# STM32G474xx register map
File version: 1.6
CPU: CM4 r0p1, little endian, MPU, FPU, 4 interrupt priority bits
Registers are 32-bit, read-write, reset 0x0 unless marked. A register's access mark holds for its fields unless they carry their own. Offsets are from the block's base; [hi:lo] are bit positions; {n}, {i} and the like mark numbered series; 'fields as' and 'values as' point back to an identical list.

## EXTI — External interrupt/event controller
Base 0x40010400
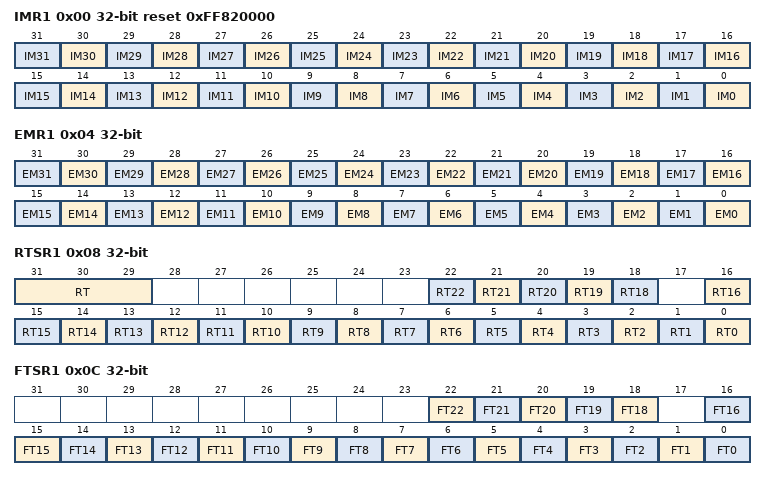
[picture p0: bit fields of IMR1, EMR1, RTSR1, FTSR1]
0x00 IMR1 reset 0xFF820000 — Interrupt mask register
  [n] IM{n} (n=0..31) — Interrupt Mask on line {n}
0x04 EMR1 — Event mask register
  [n] EM{n} (n=0..31) — Event Mask on line {n}
0x08 RTSR1 — Rising Trigger selection register
  [31:29] RT
  [n] RT{n} (n=18..22) — Rising trigger event configuration of line {n}
  [n] RT{n} (n=0..16) — Rising trigger event configuration of line {n}
0x0C FTSR1 — Falling Trigger selection register
  [n] FT{n} (n=18..22) — Falling trigger event configuration of line {n}
  [n] FT{n} (n=0..16) — Falling trigger event configuration of line {n}
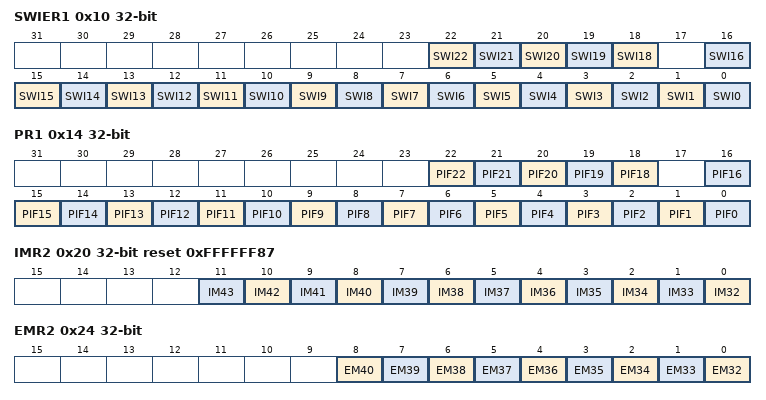
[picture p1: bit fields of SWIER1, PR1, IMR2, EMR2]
0x10 SWIER1 — Software interrupt event register
  [n] SWI{n} (n=18..22) — Software Interrupt on line {n}
  [n] SWI{n} (n=0..16) — Software Interrupt on line {n}
0x14 PR1 — Pending register
  [n] PIF{n} (n=18..22) — Pending bit {n}
  [n] PIF{n} (n=0..16) — Pending bit {n}
0x20 IMR2 reset 0xFFFFFF87 — Interrupt mask register
  [n-32] IM{n} (n=32..43) — Interrupt Mask on external/internal line {n}
0x24 EMR2 — Event mask register
  [n-32] EM{n} (n=32..40) — Event mask on external/internal line {n}
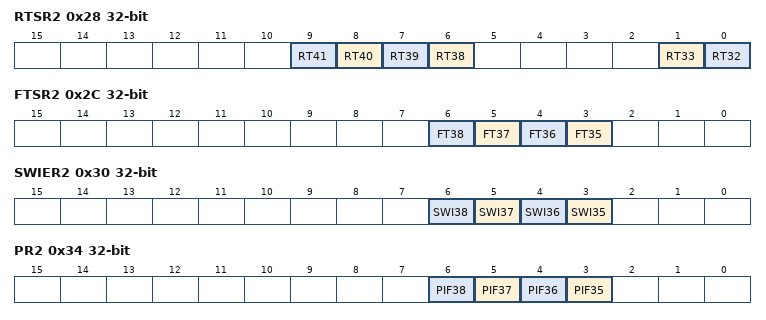
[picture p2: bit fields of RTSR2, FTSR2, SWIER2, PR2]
0x28 RTSR2 — Rising Trigger selection register
  [n-32] RT{n} (n=38..41) — Rising trigger event configuration bit of line {n}
  [1] RT33 — Rising trigger event configuration bit of line 32
  [0] RT32 — Rising trigger event configuration bit of line 32
0x2C FTSR2 — Falling Trigger selection register
  [n-32] FT{n} (n=35..38) — Falling trigger event configuration bit of line {n}
0x30 SWIER2 — Software interrupt event register
  [n-32] SWI{n} (n=35..38) — Software interrupt on line {n}
0x34 PR2 — Pending register
  [n-32] PIF{n} (n=35..38) — Pending interrupt flag on line {n}

## FMC — Flexible memory controller
Base 0xA0000000
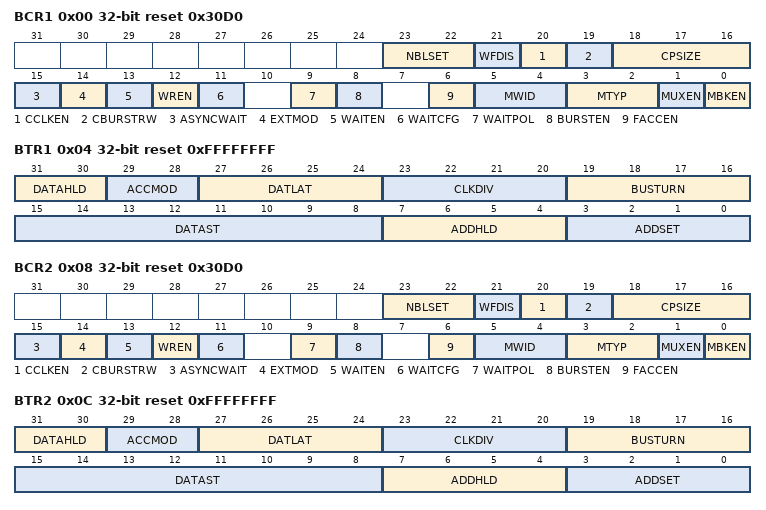
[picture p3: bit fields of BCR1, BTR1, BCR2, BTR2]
0x00 BCR1 reset 0x30D0 — SRAM/NOR-Flash chip-select control register 1
  [23:22] NBLSET, [21] WFDIS, [20] CCLKEN, [19] CBURSTRW, [18:16] CPSIZE, [15] ASYNCWAIT, [14] EXTMOD, [13] WAITEN, [12] WREN, [11] WAITCFG, [9] WAITPOL, [8] BURSTEN, [6] FACCEN, [5:4] MWID, [3:2] MTYP, [1] MUXEN, [0] MBKEN
0x04 BTR1 reset 0xFFFFFFFF — SRAM/NOR-Flash chip-select timing register 1
  [31:30] DATAHLD, [29:28] ACCMOD, [27:24] DATLAT, [23:20] CLKDIV, [19:16] BUSTURN, [15:8] DATAST, [7:4] ADDHLD, [3:0] ADDSET
0x08 BCR2 reset 0x30D0 — SRAM/NOR-Flash chip-select control register 2
  fields as BCR1
0x0C BTR2 reset 0xFFFFFFFF — SRAM/NOR-Flash chip-select timing register 2
  fields as BTR1
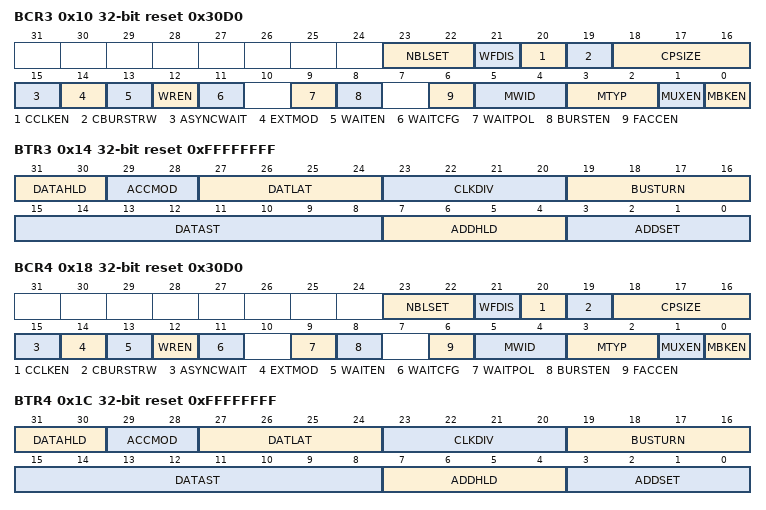
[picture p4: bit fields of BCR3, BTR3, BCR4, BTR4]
0x10 BCR3 reset 0x30D0 — SRAM/NOR-Flash chip-select control register 3
  fields as BCR1
0x14 BTR3 reset 0xFFFFFFFF — SRAM/NOR-Flash chip-select timing register 3
  fields as BTR1
0x18 BCR4 reset 0x30D0 — SRAM/NOR-Flash chip-select control register 4
  fields as BCR1
0x1C BTR4 reset 0xFFFFFFFF — SRAM/NOR-Flash chip-select timing register 4
  fields as BTR1
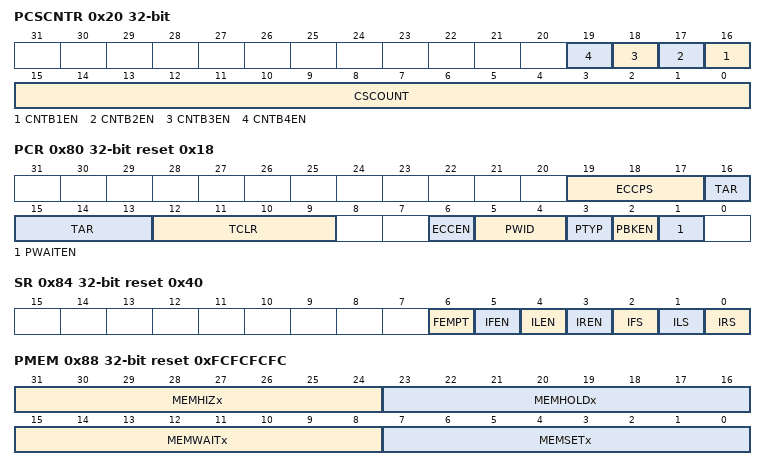
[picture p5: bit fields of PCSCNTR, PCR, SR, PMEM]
0x20 PCSCNTR — PSRAM chip select counter register
  [n+15] CNTB{n}EN (n=1..4), [15:0] CSCOUNT
0x80 PCR reset 0x18 — PC Card/NAND Flash control register 3
  [19:17] ECCPS, [16:13] TAR, [12:9] TCLR, [6] ECCEN, [5:4] PWID, [3] PTYP, [2] PBKEN, [1] PWAITEN
0x84 SR access per field reset 0x40 — FIFO status and interrupt register 3
  [6] FEMPT ro, [5] IFEN rw, [4] ILEN rw, [3] IREN rw, [2] IFS rw, [1] ILS rw, [0] IRS rw
0x88 PMEM reset 0xFCFCFCFC — Common memory space timing register 3
  [31:24] MEMHIZx, [23:16] MEMHOLDx, [15:8] MEMWAITx, [7:0] MEMSETx
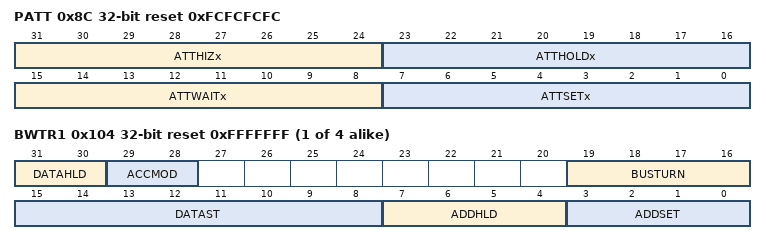
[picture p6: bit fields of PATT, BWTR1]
0x8C PATT reset 0xFCFCFCFC — Attribute memory space timing register 3
  [31:24] ATTHIZx, [23:16] ATTHOLDx, [15:8] ATTWAITx, [7:0] ATTSETx
0x94 ECCR ro — ECC result register 3
  [31:0] ECCx
{0xFC+8i} BWTR{i} reset 0xFFFFFFF (i=1..4) — SRAM/NOR-Flash write timing registers {i}
  [31:30] DATAHLD, [29:28] ACCMOD, [19:16] BUSTURN, [15:8] DATAST, [7:4] ADDHLD, [3:0] ADDSET

## Notices in the file
Copyright (c) 2020 STMicroelectronics.
SPDX-License-Identifier: Apache-2.0
Licensed under the Apache License, Version 2.0 (the "License");
you may not use this file except in compliance with the License.
You may obtain a copy of the License at
http://www.apache.org/licenses/LICENSE-2.0
Unless required by applicable law or agreed to in writing, software
distributed under the License is distributed on an "AS IS" BASIS,
WITHOUT WARRANTIES OR CONDITIONS OF ANY KIND, either express or implied.
See the License for the specific language governing permissions and
limitations under the License.
